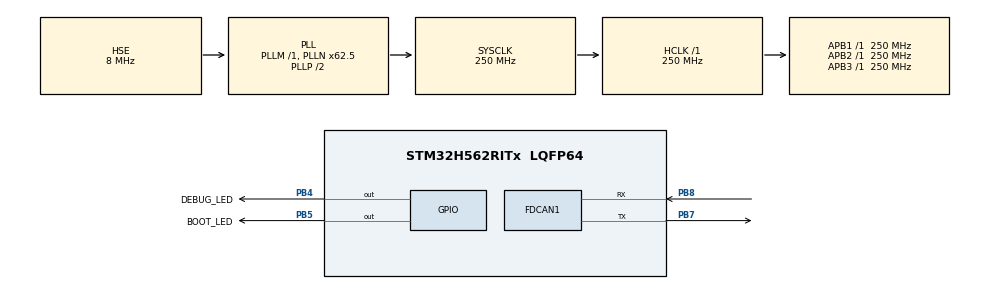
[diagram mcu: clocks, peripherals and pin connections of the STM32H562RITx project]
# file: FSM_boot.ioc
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BOOTPATH.BootPathName=LEGACY
BOOTPATH.UserSelectedBootPath=LEGACY
CORTEX_M33_NS.userName=CORTEX_M33
FDCAN1.AutoRetransmission=ENABLE
FDCAN1.CalculateBaudRateNominal=1000000
FDCAN1.CalculateTimeBitNominal=1000
FDCAN1.CalculateTimeQuantumNominal=62.5
FDCAN1.DataPrescaler=3
FDCAN1.DataSyncJumpWidth=2
FDCAN1.DataTimeSeg1=5
FDCAN1.DataTimeSeg2=2
FDCAN1.ExtFiltersNbr=1
FDCAN1.FrameFormat=FDCAN_FRAME_FD_NO_BRS
FDCAN1.NominalPrescaler=6
FDCAN1.NominalSyncJumpWidth=2
FDCAN1.NominalTimeSeg1=13
FDCAN1.NominalTimeSeg2=2
FDCAN1.StdFiltersNbr=1
Mcu.Family=STM32H5
Mcu.Name=STM32H562RITx
Mcu.Package=LQFP64
NVIC.FDCAN1_IT0_IRQn=true\:5\:0\:true\:false\:true\:true\:true\:true
NVIC.FDCAN1_IT1_IRQn=true\:5\:0\:true\:false\:true\:true\:true\:true
NVIC.PriorityGroup=NVIC_PRIORITYGROUP_4
NVIC.RCC_IRQn=true\:5\:0\:true\:false\:true\:true\:false\:true
NVIC.TIM6_IRQn=true\:15\:0\:false\:false\:true\:false\:true\:true
NVIC.TimeBase=TIM6_IRQn
NVIC.TimeBaseIP=TIM6
PA13(JTMS/SWDIO).Mode=Trace_Asynchronous_SW
PA13(JTMS/SWDIO).Signal=DEBUG_JTMS-SWDIO
PA14(JTCK/SWCLK).Mode=Trace_Asynchronous_SW
PA14(JTCK/SWCLK).Signal=DEBUG_JTCK-SWCLK
PB3(JTDO/TRACESWO).Mode=Trace_Asynchronous_SW
PB3(JTDO/TRACESWO).Signal=DEBUG_JTDO-SWO
PB4(NJTRST).GPIO_Label=DEBUG_LED
PB4(NJTRST).Signal=GPIO_Output
PB5.GPIO_Label=BOOT_LED
PB5.PinState=GPIO_PIN_SET
PB5.Signal=GPIO_Output
PB7.Mode=FDCAN_Activate
PB7.Signal=FDCAN1_TX
PB8.Mode=FDCAN_Activate
PB8.Signal=FDCAN1_RX
PH0-OSC_IN(PH0).Mode=HSE-External-Oscillator
PH0-OSC_IN(PH0).Signal=RCC_OSC_IN
PH1-OSC_OUT(PH1).Mode=HSE-External-Oscillator
PH1-OSC_OUT(PH1).Signal=RCC_OSC_OUT
ProjectManager.HeapSize=0x200
ProjectManager.StackSize=0x400
ProjectManager.TargetToolchain=EWARM V9.20
RCC.ADCFreq_Value=250000000
RCC.AHBFreq_Value=250000000
RCC.APB1Freq_Value=250000000
RCC.APB1TimFreq_Value=250000000
RCC.APB2Freq_Value=250000000
RCC.APB2TimFreq_Value=250000000
RCC.APB3Freq_Value=250000000
RCC.CSI_VALUE=4000000
RCC.CortexFreq_Value=250000000
RCC.EPOD_VALUE=8000000
RCC.FDCANClockSelection=RCC_FDCANCLKSOURCE_PLL2Q
RCC.HCLKFreq_Value=250000000
RCC.HSE_VALUE=8000000
RCC.HSI48_VALUE=48000000
RCC.HSIDiv=RCC_HSI_DIV1
RCC.HSI_VALUE=64000000
RCC.LSE_VALUE=32768
RCC.LSIRC_VALUE=32000
RCC.PLL2FRACN=0
RCC.PLL2N=24
RCC.PLL2Source=RCC_PLL2_SOURCE_HSE
RCC.PLLFRACN=4096
RCC.PLLN=62
RCC.PLLSourceVirtual=RCC_PLL1_SOURCE_HSE
RCC.PWR_Regulator_Voltage_Scale=PWR_REGULATOR_VOLTAGE_SCALE0
RCC.SYSCLKFreq_VALUE=250000000
RCC.SYSCLKSource=RCC_SYSCLKSOURCE_PLLCLK
RCC.USBFreq_Value=48000000
RCC.VCOOutputFreq_Value=500000000
VP_BOOTPATH_VS_BOOTPATH.Mode=BP_Activate
VP_CORTEX_M33_NS_VS_Hclk.Mode=Hclk_Mode
VP_MEMORYMAP_VS_MEMORYMAP.Mode=CurAppReg
VP_PWR_VS_LPOM.Mode=PowerOptimisation
VP_PWR_VS_SECSignals.Mode=Security/Privilege
VP_SYS_VS_tim6.Mode=TIM6
board=custom

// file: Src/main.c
/* USER CODE BEGIN Header */
/**
 ******************************************************************************
 * @file           : main.c
 * @brief          : Main program body
 ******************************************************************************
 * @attention
 *
 * Copyright (c) 2026 STMicroelectronics.
 * All rights reserved.
 *
 * This software is licensed under terms that can be found in the LICENSE file
 * in the root directory of this software component.
 * If no LICENSE file comes with this software, it is provided AS-IS.
 *
 ******************************************************************************
 */
/* USER CODE END Header */
#include "main.h"

/* USER CODE BEGIN Includes */
#include "bootloader.h"
#include "hw_error.hpp"
/* USER CODE END Includes */

FDCAN_HandleTypeDef hfdcan1;

void        SystemClock_Config(void);
static void MX_GPIO_Init(void);
static void MX_FDCAN1_Init(void);

int main(void)
{
    /* USER CODE BEGIN 1 */
    bootloader_preInit();
    /* USER CODE END 1 */

    /* MCU Configuration--------------------------------------------------------*/

    /* Reset of all peripherals, Initializes the Flash interface and the Systick. */
    HAL_Init();

    /* Configure the system clock */
    SystemClock_Config();

    /* Initialize all configured peripherals */
    MX_GPIO_Init();
    MX_FDCAN1_Init();
    /* USER CODE BEGIN 2 */
    bootloader_init();
    /* USER CODE END 2 */

    /* Infinite loop */
    while (1)
    {

    }
}

void SystemClock_Config(void)
{
    RCC_OscInitTypeDef RCC_OscInitStruct = { 0 };
    RCC_ClkInitTypeDef RCC_ClkInitStruct = { 0 };

    /** Configure the main internal regulator output voltage
     */
    __HAL_PWR_VOLTAGESCALING_CONFIG(PWR_REGULATOR_VOLTAGE_SCALE0);

    while (!__HAL_PWR_GET_FLAG(PWR_FLAG_VOSRDY))
    {
    }

    /** Initializes the RCC Oscillators according to the specified parameters
     * in the RCC_OscInitTypeDef structure.
     */
    RCC_OscInitStruct.OscillatorType = RCC_OSCILLATORTYPE_HSE;
    RCC_OscInitStruct.HSEState       = RCC_HSE_ON;
    RCC_OscInitStruct.PLL.PLLState   = RCC_PLL_ON;
    RCC_OscInitStruct.PLL.PLLSource  = RCC_PLL1_SOURCE_HSE;
    RCC_OscInitStruct.PLL.PLLM       = 1;
    RCC_OscInitStruct.PLL.PLLN       = 62;
    RCC_OscInitStruct.PLL.PLLP       = 2;
    RCC_OscInitStruct.PLL.PLLQ       = 2;
    RCC_OscInitStruct.PLL.PLLR       = 2;
    RCC_OscInitStruct.PLL.PLLRGE     = RCC_PLL1_VCIRANGE_3;
    RCC_OscInitStruct.PLL.PLLVCOSEL  = RCC_PLL1_VCORANGE_WIDE;
    RCC_OscInitStruct.PLL.PLLFRACN   = 4096;
    if (HAL_RCC_OscConfig(&RCC_OscInitStruct) != HAL_OK)
    {
        Error_Handler();
    }

    /** Initializes the CPU, AHB and APB buses clocks
     */
    RCC_ClkInitStruct.ClockType =
        RCC_CLOCKTYPE_HCLK | RCC_CLOCKTYPE_SYSCLK | RCC_CLOCKTYPE_PCLK1 | RCC_CLOCKTYPE_PCLK2 | RCC_CLOCKTYPE_PCLK3;
    RCC_ClkInitStruct.SYSCLKSource   = RCC_SYSCLKSOURCE_PLLCLK;
    RCC_ClkInitStruct.AHBCLKDivider  = RCC_SYSCLK_DIV1;
    RCC_ClkInitStruct.APB1CLKDivider = RCC_HCLK_DIV1;
    RCC_ClkInitStruct.APB2CLKDivider = RCC_HCLK_DIV1;
    RCC_ClkInitStruct.APB3CLKDivider = RCC_HCLK_DIV1;

    if (HAL_RCC_ClockConfig(&RCC_ClkInitStruct, FLASH_LATENCY_5) != HAL_OK)
    {
        Error_Handler();
    }

    /** Configure the programming delay
     */
    __HAL_FLASH_SET_PROGRAM_DELAY(FLASH_PROGRAMMING_DELAY_2);
}

static void MX_FDCAN1_Init(void)
{

    hfdcan1.Instance                  = FDCAN1;
    hfdcan1.Init.ClockDivider         = FDCAN_CLOCK_DIV1;
    hfdcan1.Init.FrameFormat          = FDCAN_FRAME_FD_NO_BRS;
    hfdcan1.Init.Mode                 = FDCAN_MODE_NORMAL;
    hfdcan1.Init.AutoRetransmission   = ENABLE;
    hfdcan1.Init.TransmitPause        = DISABLE;
    hfdcan1.Init.ProtocolException    = DISABLE;
    hfdcan1.Init.NominalPrescaler     = 6;
    hfdcan1.Init.NominalSyncJumpWidth = 2;
    hfdcan1.Init.NominalTimeSeg1      = 13;
    hfdcan1.Init.NominalTimeSeg2      = 2;
    hfdcan1.Init.DataPrescaler        = 3;
    hfdcan1.Init.DataSyncJumpWidth    = 2;
    hfdcan1.Init.DataTimeSeg1         = 5;
    hfdcan1.Init.DataTimeSeg2         = 2;
    hfdcan1.Init.StdFiltersNbr        = 1;
    hfdcan1.Init.ExtFiltersNbr        = 1;
    hfdcan1.Init.TxFifoQueueMode      = FDCAN_TX_FIFO_OPERATION;
    if (HAL_FDCAN_Init(&hfdcan1) != HAL_OK)
    {
        Error_Handler();
    }
}

static void MX_GPIO_Init(void)
{
    GPIO_InitTypeDef GPIO_InitStruct = { 0 };

    /* GPIO Ports Clock Enable */
    __HAL_RCC_GPIOH_CLK_ENABLE();
    __HAL_RCC_GPIOA_CLK_ENABLE();
    __HAL_RCC_GPIOB_CLK_ENABLE();

    /*Configure GPIO pin Output Level */
    HAL_GPIO_WritePin(DEBUG_LED_GPIO_Port, DEBUG_LED_Pin, GPIO_PIN_RESET);

    /*Configure GPIO pin Output Level */
    HAL_GPIO_WritePin(BOOT_LED_GPIO_Port, BOOT_LED_Pin, GPIO_PIN_SET);

    /*Configure GPIO pins : DEBUG_LED_Pin BOOT_LED_Pin */
    GPIO_InitStruct.Pin   = DEBUG_LED_Pin | BOOT_LED_Pin;
    GPIO_InitStruct.Mode  = GPIO_MODE_OUTPUT_PP;
    GPIO_InitStruct.Pull  = GPIO_NOPULL;
    GPIO_InitStruct.Speed = GPIO_SPEED_FREQ_LOW;
    HAL_GPIO_Init(GPIOB, &GPIO_InitStruct);

}

void HAL_TIM_PeriodElapsedCallback(TIM_HandleTypeDef *htim)
{
    if (htim->Instance == TIM6)
    {
        HAL_IncTick();
    }
}

void Error_Handler(void)
{
    __disable_irq();
    while (1)
    {
    }
}
